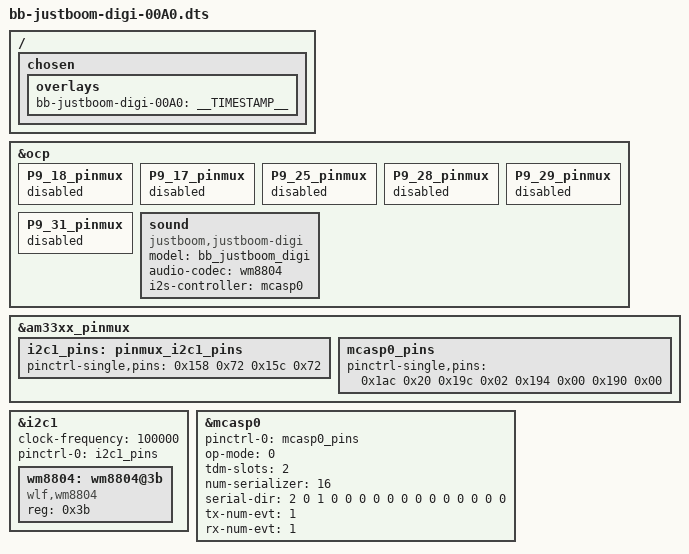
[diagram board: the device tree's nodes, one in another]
/*
 * Copyright (C) 2012 Texas Instruments Incorporated - http://www.ti.com/
 *
 * This program is free software; you can redistribute it and/or modify
 * it under the terms of the GNU General Public License version 2 as
 * published by the Free Software Foundation.
 */

/dts-v1/;
/plugin/;

/ {
	/*
	 * Helper to show loaded overlays under: /proc/device-tree/chosen/overlays/
	 */
	fragment@0 {
		target-path="/";
		__overlay__ {

			chosen {
				overlays {
					bb-justboom-digi-00A0 = __TIMESTAMP__;
				};
			};
		};
	};

	/*
	 * Free up the pins used by the cape from the pinmux helpers.
	 */
	fragment@1 {
		target = <&ocp>;
		__overlay__ {
			P9_18_pinmux { status = "disabled"; };	/* P9_18: spi0_d1.i2c1_sda,SLEWCTRL_SLOW | INPUT_PULLUP |MODE2*/
			P9_17_pinmux { status = "disabled"; };	/* P9_17: spi0_cs0.i2c1_scl,SLEWCTRL_SLOW | INPUT_PULLUP | MODE2*/

			P9_25_pinmux { status = "disabled"; };	/* P9_25: mcasp0_ahclkx,	     MODE0 | INPUT_PULLDOWN  */
			P9_28_pinmux { status = "disabled"; };	/* P9_28: mcasp0_ahclkr,	     MODE2 | OUTPUT_PULLDOWN */
			P9_29_pinmux { status = "disabled"; };	/* P9_29: mcasp0_fsx,		     MODE0 | OUTPUT_PULLDOWN */
			P9_31_pinmux { status = "disabled"; };	/* P9_31: mcasp0_aclkr.mcasp0_aclkx, MODE0 | OUTPUT_PULLDOWN */ 
		};
	};

	fragment@2 {
		target = <&am33xx_pinmux>;
		__overlay__ {

			i2c1_pins: pinmux_i2c1_pins {
				pinctrl-single,pins = <
					0x158 0x72	/* P9_18: spi0_d1.i2c1_sda,SLEWCTRL_SLOW | INPUT_PULLUP |MODE2*/
					0x15c 0x72	/* P9_17: spi0_cs0.i2c1_scl,SLEWCTRL_SLOW | INPUT_PULLUP | MODE2*/
				>;
			};

			mcasp0_pins: mcasp0_pins {
				pinctrl-single,pins = <
					0x1ac 0x20	/* P9_25: mcasp0_ahclkx,	     MODE0 | INPUT_PULLDOWN  */
					0x19c 0x02	/* P9_28: mcasp0_ahclkr,	     MODE2 | OUTPUT_PULLDOWN */
					0x194 0x00	/* P9_29: mcasp0_fsx,		     MODE0 | OUTPUT_PULLDOWN */
					0x190 0x00	/* P9_31: mcasp0_aclkr.mcasp0_aclkx, MODE0 | OUTPUT_PULLDOWN */ 
				>;
			};
		};
	};

	fragment@3 {
		target = <&i2c1>;
		__overlay__ {
			#address-cells = <1>;
			#size-cells = <0>;
			clock-frequency = <100000>;
			status = "okay";
			pinctrl-names = "default";
			pinctrl-0 = <&i2c1_pins>;

			wm8804: wm8804@3b {
				#sound-dai-cells = <0>;
				compatible = "wlf,wm8804";
				reg = <0x3b>;
				/*PVDD-supply = <&vdd_3v3_reg>;
				DVDD-supply = <&vdd_3v3_reg>;*/
				status = "okay";
			};
		};
	};

	fragment@4 {
		target = <&mcasp0>;
		__overlay__ {
			pinctrl-names = "default";
			pinctrl-0 = <&mcasp0_pins>;

			status = "okay";

			op-mode = <0>;          /* MCASP_IIS_MODE */
			tdm-slots = <2>;
			num-serializer = <16>;
			serial-dir = <  /* 0: INACTIVE, 1: TX, 2: RX */
				2 0 1 0
				0 0 0 0
				0 0 0 0
				0 0 0 0
			>;
			tx-num-evt = <1>;
			rx-num-evt = <1>;
		};
	};

	fragment@5 {
		target = <&ocp>;
		__overlay__ {
			sound {
				compatible = "justboom,justboom-digi";
				model = "bb_justboom_digi";
				audio-codec = <&wm8804>;
				i2s-controller = <&mcasp0>;
			};
		};

	};
};
